# cyt3dl register map
Vendor: Cypress Semiconductor; Series: cyt3dl; File version: 1.0
CPU: CM7 r0p1, little endian, MPU, FPU, VTOR, 3 interrupt priority bits
Registers are 32-bit, read-write, reset 0x0 unless marked. A register's access mark holds for its fields unless they carry their own. Offsets are from the block's base; [hi:lo] are bit positions; lines under a group give offsets from that group; {n}, {i} and the like mark numbered series.

## VIDEOSS0 (part 17 of 18) — Video and Graphics Subsystem IP
Base 0x40A00000
0xF0000 INFRA group — Bus infrastructure
  0x00 VRPU group — VRPU configuration.
    0x00 RD0_CTL reset 0x300 — VRAM Protection for read master with ID=0
      [9:8] PRIO — Device wide bus arbitration priority setting ('0': highest priority, '3': lowest priority). Masters with the same priority setting form a 'priority group'. Within a 'priority group', roundrobin arbitration is performed.
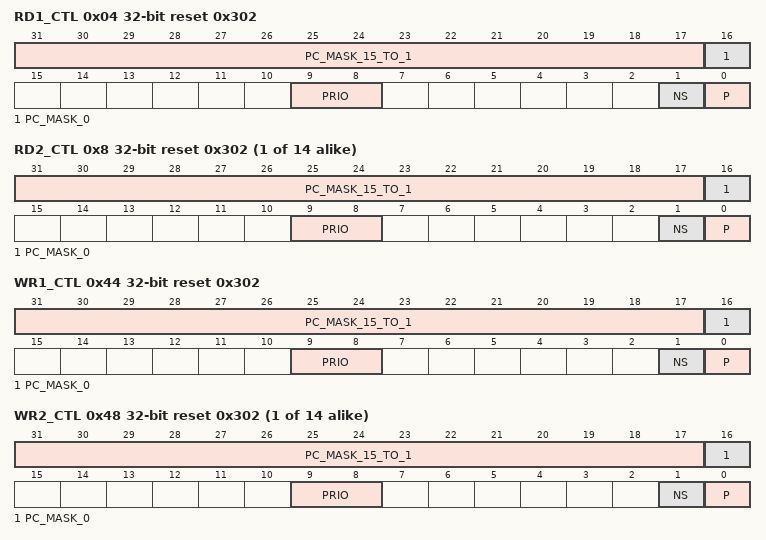
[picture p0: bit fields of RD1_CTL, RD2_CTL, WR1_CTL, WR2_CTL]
    0x04 RD1_CTL reset 0x302 — VRAM Protection for read master with ID=1
      [31:17] PC_MASK_15_TO_1 — Protection context mask for protection contexts '15' downto '1'. Bit PC_MASK_15_TO_1[i] indicates if the GFX_MPU_RDx RD_CTL.PC[3:0] protection context field can be set to the value 'i+1': - PC_MASK_15_TO_1[i] is '0': GFX_MPU_RDx RD_CTL.PC[3:0] can NOT be set to 'i+1'; and PC[3:0] is not changed. If the protection context of the write transfer is '0', protection is not applied and PC[3:0] can be changed. - PC_MASK_15_TO_1[i] is '1': GFX_MPU_RDx RD_CTL.PC[3:0] can be set to 'i+1'. Note: When CPUSS_CM0_PC_CTL.VALID[i] is '1' (the associated protection context handler is valid), write transfers to PC_MASK_15_TO_1[i-1] always write '0', regardless of data written. This ensures that when valid protection context handlers are used to enter protection contexts 1, 2 or 3 through (HW modifies CPUSS_PROT_MPU0 MS_CTL.PC[3:0] on entry of the handler), it is NOT possible for SW to enter those protection contexts (SW modifies GFX_MPU_RDx RD_CTL.PC[3:0]).
      [16] PC_MASK_0 ro — Protection context mask for protection context '0'. This field is a constant '0'.
      [9:8] PRIO — See RD0_CTL.PRIO
      [1] NS — Security setting ('0': secure mode; '1': non-secure mode).
      [0] P — Privileged setting ('0': user mode; '1': privileged mode).
    {0x0+4k} RD{k}_CTL reset 0x302 (k=2..15) — VRAM Protection for read master with ID={k}
      [31:17] PC_MASK_15_TO_1 — See RD1_CTL.PC_MASK_15_TO_1.
      [16] PC_MASK_0 ro — See RD1_CTL.PC_MASK_0.
      [9:8] PRIO — See RD0_CTL.PRIO
      [1] NS — See RD1_CTL.NS.
      [0] P — See RD1_CTL.P.
    0x40 WR0_CTL reset 0x300 — VRAM Protection for write master with ID=0
      [9:8] PRIO — See RD0_CTL.PRIO
    0x44 WR1_CTL reset 0x302 — VRAM Protection for write master with ID=1
      [31:17] PC_MASK_15_TO_1 — Protection context mask for protection contexts '15' downto '1'. Bit PC_MASK_15_TO_1[i] indicates if the GFX_MPU_WRx WR_CTL.PC[3:0] protection context field can be set to the value 'i+1': - PC_MASK_15_TO_1[i] is '0': GFX_MPU_WRx WR_CTL.PC[3:0] can NOT be set to 'i+1'; and PC[3:0] is not changed. If the protection context of the write transfer is '0', protection is not applied and PC[3:0] can be changed. - PC_MASK_15_TO_1[i] is '1': GFX_MPU_WRx WR_CTL.PC[3:0] can be set to 'i+1'. Note: When CPUSS_CM0_PC_CTL.VALID[i] is '1' (the associated protection context handler is valid), write transfers to PC_MASK_15_TO_1[i-1] always write '0', regardless of data written. This ensures that when valid protection context handlers are used to enter protection contexts 1, 2 or 3 through (HW modifies CPUSS_PROT_MPU0 MS_CTL.PC[3:0] on entry of the handler), it is NOT possible for SW to enter those protection contexts (SW modifies GFX_MPU_WRx WR_CTL.PC[3:0]).
      [16] PC_MASK_0 ro — See RD1_CTL.PC_MASK_0.
      [9:8] PRIO — See RD0_CTL.PRIO
      [1] NS — See RD1_CTL.NS.
      [0] P — See RD1_CTL.P.
    {0x40+4k} WR{k}_CTL reset 0x302 (k=2..15) — VRAM Protection for write master with ID={k}
      [31:17] PC_MASK_15_TO_1 — See WR1_CTL.PC_MASK_15_TO_1.
      [16] PC_MASK_0 ro — See RD1_CTL.PC_MASK_0.
      [9:8] PRIO — See RD0_CTL.PRIO
      [1] NS — See RD1_CTL.NS.
      [0] P — See RD1_CTL.P.
    {0x2000+0x40*k} VRPU_STRUCT[{k}] (k=0..7) group — VRPU structures.
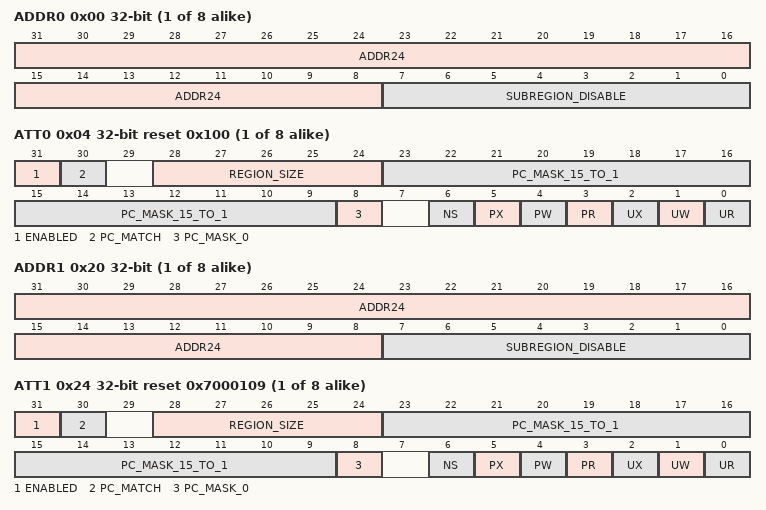
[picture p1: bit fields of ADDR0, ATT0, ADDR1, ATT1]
      0x00 ADDR0 reset not defined — VRPU region address 0 (slave structure)
        [31:8] ADDR24 — This field specifies the most significant bits of the 32-bit address of an address region. The region size is defined by ATT0.REGION_SIZE. A region of n Byte is always n Byte aligned. As a result, some of the lesser significant address bits of ADDR24 may be ignored in determining whether a bus transfer address is within an address region. E.g., a 64 KByte address region (REGION_SIZE is '15') is 64 KByte aligned, and ADDR24[7:0] are ignored.
        [7:0] SUBREGION_DISABLE — This field is used to individually disabled the eight equally sized subregions in which a region is partitioned. Subregion disable: Bit 0: subregion 0 disable. Bit 1: subregion 1 disable. Bit 2: subregion 2 disable. Bit 3: subregion 3 disable. Bit 4: subregion 4 disable. Bit 5: subregion 5 disable. Bit 6: subregion 6 disable. Bit 7: subregion 7 disable. E.g., a 64 KByte address region (ATT0.REGION_SIZE is '15') has eight 8 KByte subregions. The access control as defined by ATT0 applies if the bus transfer address is within the address region AND the addressed subregion is NOT disabled. Note that the smallest region size is 256 B and the smallest subregion size is 32 B.
      0x04 ATT0 reset 0x100 (reset mask 0x80000100) — VRPU region attributes 0 (slave structure)
        [31] ENABLED — Region enable: '0': Disabled. A disabled region will never result in a match on the bus transfer address. '1': Enabled. Note: a disabled address region performs logic gating to reduce dynamic power consumption.
        [30] PC_MATCH — This field specifies if the PC field participates in the 'matching' process or the 'access evaluation' process: '0': PC field participates in 'access evaluation'. '1': PC field participates in 'matching'. Note that it is possible to define different access control for multiple protection contexts by using multiple protection structures with the same address region and PC_MATCH set to '1'.
        [28:24] REGION_SIZE — This field specifies the region size: '0'-'6': Undefined. '7': 256 B region '8': 512 B region '9': 1 KB region '10': 2 KB region '11': 4 KB region '12': 8 KB region '13': 16 KB region '14': 32 KB region '15': 64 KB region '16': 128 KB region '17': 256 KB region '18': 512 KB region '19': 1 MB region '20': 2 MB region '21': 4 MB region '22': 8 MB region '23': 16 MB region '24': 32 MB region '25': 64 MB region '26': 128 MB region '27': 256 MB region '28': 512 MB region '39': 1 GB region '30': 2 GB region '31': 4 GB region
        [23:9] PC_MASK_15_TO_1 — This field specifies protection context identifier based access control. Bit i: protection context i+1 enable. If '0', protection context i+1 access is disabled; i.e. not allowed. If '1', protection context i+1 access is enabled; i.e. allowed.
        [8] PC_MASK_0 ro — This field specifies protection context identifier based access control for protection context '0'.
        [6] NS — Non-secure: '0': Secure (secure accesses allowed, non-secure access NOT allowed). '1': Non-secure (both secure and non-secure accesses allowed).
        [5] PX — Privileged execute enable: '0': Disabled (privileged, execute accesses are NOT allowed). '1': Enabled (privileged, execute accesses are allowed).
        [4] PW — Privileged write enable: '0': Disabled (privileged, write accesses are NOT allowed). '1': Enabled (privileged, write accesses are allowed).
        [3] PR — Privileged read enable: '0': Disabled (privileged, read accesses are NOT allowed). '1': Enabled (privileged, read accesses are allowed).
        [2] UX — User execute enable: '0': Disabled (user, execute accesses are NOT allowed). '1': Enabled (user, execute accesses are allowed).
        [1] UW — User write enable: '0': Disabled (user, write accesses are NOT allowed). '1': Enabled (user, write accesses are allowed).
        [0] UR — User read enable: '0': Disabled (user, read accesses are NOT allowed). '1': Enabled (user, read accesses are allowed).
      0x20 ADDR1 ro — VRPU region address 1 (master structure)
        [31:8] ADDR24 — This field specifies the most significant bits of the 32-bit address of an address region. 'ADDR_DEF1': base address of structure. Note: this field is read-only.
        [7:0] SUBREGION_DISABLE — This field is used to individually disabled the eight equally sized subregions in which a region is partitioned. Subregion disable: Bit 0: subregion 0 disable. Bit 1: subregion 1 disable. Bit 2: subregion 2 disable. Bit 3: subregion 3 disable. Bit 4: subregion 4 disable. Bit 5: subregion 5 disable. Bit 6: subregion 6 disable. Bit 7: subregion 7 disable. Two out of a total of eight 32 B subregions are enabled. These subregions includes region structures 0 and 1. Note: this field is read-only.
      0x24 ATT1 reset 0x7000109 (reset mask 0x9F00012D) — VRPU region attributes 1 (master structure)
        [31] ENABLED — Region enable: '0': Disabled. A disabled region will never result in a match on the bus transfer address. '1': Enabled.
        [30] PC_MATCH — This field specifies if the PC field participates in the 'matching' process or the 'access evaluation' process: '0': PC field participates in 'access evaluation'. '1': PC field participates in 'matching'. Note that it is possible to define different access control for multiple protection contexts by using multiple protection structures with the same address region and PC_MATCH set to '1'.
        [28:24] REGION_SIZE ro — This field specifies the region size: '7': 256 B region (8 32 B subregions) Note: this field is read-only.
        [23:9] PC_MASK_15_TO_1 — This field specifies protection context identifier based access control. Bit i: protection context i+1 enable. If '0', protection context i+1 access is disabled; i.e. not allowed. If '1', protection context i+1 access is enabled; i.e. allowed.
        [8] PC_MASK_0 ro — This field specifies protection context identifier based access control for protection context '0'.
        [6] NS — Non-secure: '0': Secure (secure accesses allowed, non-secure access NOT allowed). '1': Non-secure (both secure and non-secure accesses allowed).
        [5] PX ro — Privileged execute enable: '0': Disabled (privileged, execute accesses are NOT allowed). '1': Enabled (privileged, execute accesses are allowed). Note that this register is constant '0'; i.e. privileged execute accesses are NEVER allowed.
        [4] PW — Privileged write enable: '0': Disabled (privileged, write accesses are NOT allowed). '1': Enabled (privileged, write accesses are allowed).
        [3] PR ro — Privileged read enable: '0': Disabled (privileged, read accesses are NOT allowed). '1': Enabled (privileged, read accesses are allowed). Note that this register is constant '1'; i.e. privileged read accesses are ALWAYS allowed.
        [2] UX ro — User execute enable: '0': Disabled (user, execute accesses are NOT allowed). '1': Enabled (user, execute accesses are allowed). Note that this register is constant '0'; i.e. user execute accesses are NEVER allowed.
        [1] UW — User write enable: '0': Disabled (user, write accesses are NOT allowed). '1': Enabled (user, write accesses are allowed).
        [0] UR ro — User read enable: '0': Disabled (user, read accesses are NOT allowed). '1': Enabled (user, read accesses are allowed). Note that this register is constant '1'; i.e. user read accesses are ALWAYS allowed.
  {0x4000+0x400*j} GFX_MPU_RD[{j}] (j=0..15) group — MPU configuration for read masters.
    0x00 RD_CTL — Memory protection context for AXI read master
      [3:0] PC — Active protection context. Modifications to this field are constrained by the associated RDx_CTL.PC_MASK_0 and RDx_CTL.PC_MASK_15_TO_1[] fields.
  {0x8000+0x400*j} GFX_MPU_WR[{j}] (j=0..15) group — MPU configuration for write masters.
    0x00 WR_CTL — Memory protection context for AXI write master
      [3:0] PC — Active protection context. Modifications to this field are constrained by the associated WRx_CTL.PC_MASK_0 and WRx_CTL.PC_MASK_15_TO_1[] fields.

## Notices in the file
Copyright 2016-2019, Cypress Semiconductor Corporation.  All rights reserved.
You may use this file only in accordance with the license, terms, conditions,
disclaimers, and limitations in the end user license agreement accompanying
the software package with which this file was provided.
